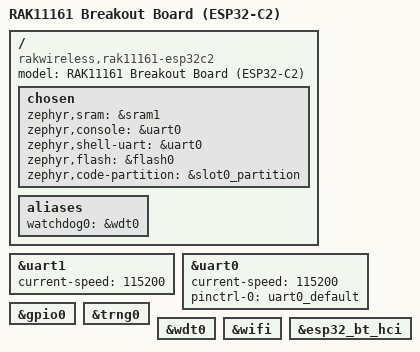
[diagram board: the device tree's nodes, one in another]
/*
 * Copyright (c) 2026 RAKwireless Technology Limited <www.rakwireless.com>
 * JaeHwan Jin <jaehwan.jin@rakwireless.com>
 * SPDX-License-Identifier: Apache-2.0
 */

/dts-v1/;
#include <rakwireless/rak11160_esp32c2.dtsi>
#include <espressif/partitions_0x0_default_2M.dtsi>
#include "rak11161_esp32c2-pinctrl.dtsi"

/ {
	model = "RAK11161 Breakout Board (ESP32-C2)";
	compatible = "rakwireless,rak11161-esp32c2";

	chosen {
		zephyr,sram = &sram1;
		zephyr,console = &uart0;
		zephyr,shell-uart = &uart0;
		zephyr,flash = &flash0;
		zephyr,code-partition = &slot0_partition;
	};

	aliases {
		watchdog0 = &wdt0;
	};
};

/*
 * Common board-level label for
 * the on-module ESP32-C2 <-> STM32WLE5 coprocessor UART link.
 */
coproc_uart: &uart1 {
	status = "okay";
	current-speed = <115200>;
};

&uart0 {
	status = "okay";
	current-speed = <115200>;
	pinctrl-0 = <&uart0_default>;
	pinctrl-names = "default";
};

&gpio0 {
	status = "okay";
};

&trng0 {
	status = "okay";
};

&wdt0 {
	status = "okay";
};

&wifi {
	status = "okay";
};

&esp32_bt_hci {
	status = "okay";
};
